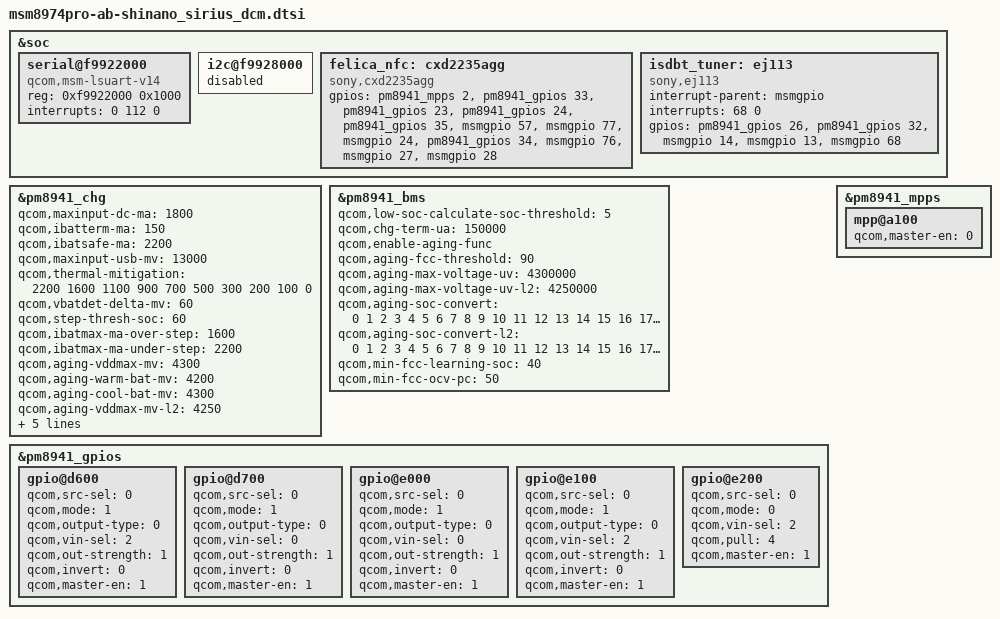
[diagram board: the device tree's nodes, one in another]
/* arch/arm/boot/dts/msm8974pro-ab-shinano_sirius_dcm.dtsi
 *
 * Copyright (C) 2013 Sony Mobile Communications Inc.
 *
 * Author: Shougo Watanabe <Shougo.X.Watanabe@sonymobile.com>
 *
 * This program is free software; you can redistribute it and/or modify
 * it under the terms of the GNU General Public License version 2 and
 * only version 2 as published by the Free Software Foundation.
 *
 * This program is distributed in the hope that it will be useful,
 * but WITHOUT ANY WARRANTY; without even the implied warranty of
 * MERCHANTABILITY or FITNESS FOR A PARTICULAR PURPOSE.  See the
 * GNU General Public License for more details.
 *
 *
 * NOTE: This file has been modified by Sony Mobile Communications Inc.
 * Modifications are licensed under the License.
 */

&soc {
	/* UART : BLSP6 */
	serial@f9922000 {
		compatible = "qcom,msm-lsuart-v14";
		reg = <0xf9922000 0x1000>;
		interrupts = <0 112 0>;
		status = "ok";
	};

	/* I2C : BLSP6 */
	i2c@f9928000 {
		status = "disabled";
	};

	felica_nfc: cxd2235agg {
		compatible = "sony,cxd2235agg";
		gpios = <&pm8941_mpps 2 0>,   /* LOCK */
			<&pm8941_gpios 33 0>, /* FF */
			<&pm8941_gpios 23 0>, /* PON */
			<&pm8941_gpios 24 0>, /* LDO EN */
			<&pm8941_gpios 35 0>, /* INTU */
			<&msmgpio 57 0>,      /* HSEL */
			<&msmgpio 77 0>,      /* RFS */
			<&msmgpio 24 0>,      /* INT */
			<&pm8941_gpios 34 0>, /* PVDD */
			<&msmgpio 76 0>,      /* KOTO_PWR */
			<&msmgpio 27 0>,      /* TX */
			<&msmgpio 28 0>;      /* RX */
	};

	isdbt_tuner: ej113 {
		compatible = "sony,ej113";
		interrupt-parent = <&msmgpio>;
		interrupts = <68 0>;
		gpios = <&pm8941_gpios 26 0>, /* ANT_POWER */
			<&pm8941_gpios 32 0>, /* ANT_SWITCH */
			<&msmgpio 14 0>, /* TUNER_POWER */
			<&msmgpio 13 0>, /* TUNER_RESET */
			<&msmgpio 68 0>; /* TUNER_INT */
	};
};

&pm8941_chg {
	qcom,maxinput-dc-ma = <1800>;
	qcom,ibatterm-ma = <150>;
	qcom,ibatsafe-ma = <2200>;
	qcom,maxinput-usb-mv = <13000>;
	qcom,thermal-mitigation = <2200 1600 1100 900 700 500 300 200 100 0>;
	qcom,vbatdet-delta-mv = <60>;
	qcom,step-thresh-soc = <60>;
	qcom,ibatmax-ma-over-step = <1600>;
	qcom,ibatmax-ma-under-step = <2200>;
	qcom,aging-vddmax-mv = <4300>;
	qcom,aging-warm-bat-mv = <4200>;
	qcom,aging-cool-bat-mv = <4300>;
	qcom,aging-vddmax-mv-l2 = <4250>;
	qcom,aging-warm-bat-mv-l2 = <4200>;
	qcom,aging-cool-bat-mv-l2 = <4250>;
	qcom,aging-ibatmax-ma = <1600>;
	qcom,aging-warm-ibatmax-ma = <900>;
	qcom,aging-cool-ibatmax-ma = <900>;
};

&pm8941_bms {
	qcom,low-soc-calculate-soc-threshold = <5>;
	qcom,chg-term-ua = <150000>;
	qcom,enable-aging-func;
	qcom,aging-fcc-threshold = <90>;
	qcom,aging-max-voltage-uv = <4300000>;
	qcom,aging-max-voltage-uv-l2 = <4250000>;
	qcom,aging-soc-convert = <0 1 2 3 4 5 6 7 8 9 10 11 12 13 14 15 16 17
		18 19 20 21 22 23 24 25 26 27 28 29 30 32 33 34 35 36 37 38 39
		40 41 42 44 45 46 47 48 49 50 51 52 53 54 56 57 58 59 60 61 62
		63 64 65 66 68 69 70 71 72 73 74 75 76 77 78 80 81 82 83 84 85
		86 87 88 89 90 91 92 93 94 95 96 97 98 99 100 100 100 100 100
		100>;
	qcom,aging-soc-convert-l2 = <0 1 2 3 4 5 6 7 8 9 10 11 12 13 14 15 16 17
		18 19 20 21 22 24 25 26 27 29 30 31 32 34 35 36 37 39 40 41 42
		44 45 46 47 49 50 51 52 54 55 56 57 59 60 61 62 64 65 66 67 69
		70 71 72 74 75 76 77 79 80 81 82 83 84 85 86 87 88 89 90 91 92
		93 94 95 96 97 98 99 100 100 100 100 100 100 100 100 100 100 100
		100 100>;
	qcom,min-fcc-learning-soc = <40>;
	qcom,min-fcc-ocv-pc = <50>;
};

&pm8941_gpios {
	/* GPIO_23: FELICA_PON */
	gpio@d600 {
		qcom,src-sel = <0>;		/* GPIO */
		qcom,mode = <1>;		/* Out */
		qcom,output-type = <0>;		/* CMOS */
		qcom,vin-sel = <2>;		/* S3 */
		qcom,out-strength = <1>;	/* Low */
		qcom,invert = <0>;		/* Low */
		qcom,master-en = <1>;		/* Enable */
		status = "ok";
	};

	/* GPIO_24: FELICA_EXT_LDO_EN */
	gpio@d700 {
		qcom,src-sel = <0>;		/* GPIO */
		qcom,mode = <1>;		/* Out */
		qcom,output-type = <0>;		/* CMOS */
		qcom,vin-sel = <0>;		/* VPH */
		qcom,out-strength = <1>;	/* Low */
		qcom,invert = <0>;		/* Low */
		qcom,master-en = <1>;		/* Enable */
		status = "ok";
	};

	/* GPIO_33: FELICA_FF */
	gpio@e000 {
		qcom,src-sel = <0>;		/* GPIO */
		qcom,mode = <1>;		/* Out */
		qcom,output-type = <0>;		/* CMOS */
		qcom,vin-sel = <0>;		/* VPH */
		qcom,out-strength = <1>;	/* Low */
		qcom,invert = <0>;		/* Low */
		qcom,master-en = <1>;		/* Enable */
		status = "ok";
	};

	/* GPIO_34: NFC_FELICA_PVDD_EN */
	gpio@e100 {
		qcom,src-sel = <0>;		/* GPIO */
		qcom,mode = <1>;		/* Out */
		qcom,output-type = <0>;		/* CMOS */
		qcom,vin-sel = <2>;		/* S3 */
		qcom,out-strength = <1>;	/* Low */
		qcom,invert = <0>;		/* Low */
		qcom,master-en = <1>;		/* Enable */
		status = "ok";
	};

	/* GPIO_35: S_COMBO_INTU */
	gpio@e200 {
		qcom,src-sel = <0>;		/* GPIO */
		qcom,mode = <0>;		/* In */
		qcom,vin-sel = <2>;		/* S3 */
		qcom,pull = <4>;		/* PD */
		qcom,master-en = <1>;		/* Enable */
		status = "ok";
	};
};

&pm8941_mpps {
	/* MPP_2: FELICA_LOCK */
	mpp@a100 {
		qcom,master-en = <0>;		/* Disable */
		status = "ok";
	};
};
